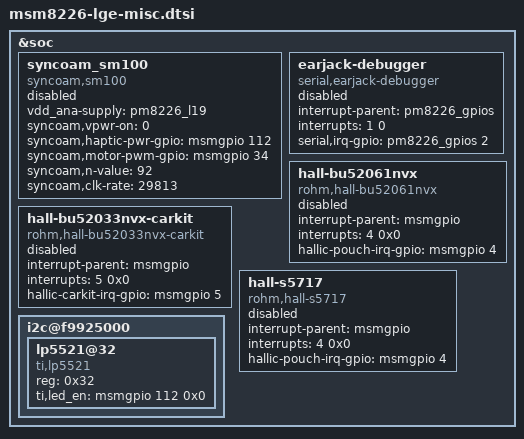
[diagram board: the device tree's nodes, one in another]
/* Copyright (c) 2012, Code Aurora Forum. All rights reserved.
 *
 * This program is free software; you can redistribute it and/or modify
 * it under the terms of the GNU General Public License version 2 and
 * only version 2 as published by the Free Software Foundation.
 *
 * This program is distributed in the hope that it will be useful,
 * but WITHOUT ANY WARRANTY; without even the implied warranty of
 * MERCHANTABILITY or FITNESS FOR A PARTICULAR PURPOSE.  See the
 * GNU General Public License for more details.
 */

&soc {
	syncoam_sm100 {
		compatible = "syncoam,sm100";
		status = "disable";
		vdd_ana-supply = <&pm8226_l19>;
		syncoam,vpwr-on = <0>;
		syncoam,haptic-pwr-gpio = <&msmgpio 112 0x00>;
		syncoam,motor-pwm-gpio = <&msmgpio 34 0x00>;
		syncoam,n-value = <92>;
		syncoam,clk-rate = <29813>;
	};

	earjack-debugger {
		compatible = "serial,earjack-debugger";
		status = "disable";
		interrupt-parent = <&pm8226_gpios>;
		interrupts = <1 0>;
		serial,irq-gpio = <&pm8226_gpios 2 0x0>;
	};

    hall-bu52061nvx {
        compatible = "rohm,hall-bu52061nvx";
        interrupt-parent = <&msmgpio>;
        interrupts = <4 0x0>;
        hallic-pouch-irq-gpio = <&msmgpio 4 0x00>;
        status = "disable";
    };

    hall-bu52033nvx-carkit {
        compatible = "rohm,hall-bu52033nvx-carkit";
        interrupt-parent = <&msmgpio>;
        interrupts = <5 0x0>;
        hallic-carkit-irq-gpio = <&msmgpio 5 0x00>;
        status = "disable";
    };

    hall-s5717 {
        compatible = "rohm,hall-s5717";
        interrupt-parent = <&msmgpio>;
        interrupts = <4 0x0>;
        hallic-pouch-irq-gpio = <&msmgpio 4 0x00>;
        status = "disable";
    };

    i2c@f9925000 {
    	lp5521@32 {
    		compatible = "ti,lp5521";
    		status = "ok";
    		reg = <0x32>;
    		ti,led_en = <&msmgpio 112 0x0>;
    	};
    };
};
